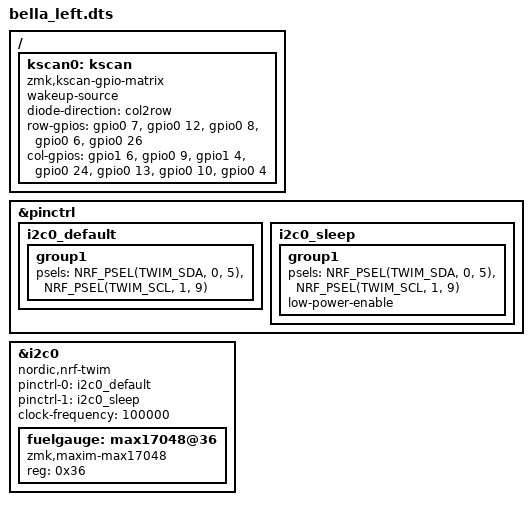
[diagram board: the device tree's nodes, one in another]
/*
 * Copyright (c) 2023 The ZMK Contributors
 *
 * SPDX-License-Identifier: MIT
 */

#include "bella.dtsi"

/{
kscan0: kscan {
    compatible = "zmk,kscan-gpio-matrix";
    wakeup-source;
    diode-direction = "col2row";
    row-gpios
        = <&gpio0 7 (GPIO_ACTIVE_HIGH | GPIO_PULL_DOWN)>
        , <&gpio0 12 (GPIO_ACTIVE_HIGH | GPIO_PULL_DOWN)>
        , <&gpio0 8 (GPIO_ACTIVE_HIGH | GPIO_PULL_DOWN)>
        , <&gpio0 6 (GPIO_ACTIVE_HIGH | GPIO_PULL_DOWN)>
        , <&gpio0 26 (GPIO_ACTIVE_HIGH | GPIO_PULL_DOWN)>
        ;
    col-gpios
        = <&gpio1 6 GPIO_ACTIVE_HIGH>
        , <&gpio0 9 GPIO_ACTIVE_HIGH>
        , <&gpio1 4 GPIO_ACTIVE_HIGH>
        , <&gpio0 24 GPIO_ACTIVE_HIGH>
        , <&gpio0 13 GPIO_ACTIVE_HIGH>
        , <&gpio0 10 GPIO_ACTIVE_HIGH>
        , <&gpio0 4 GPIO_ACTIVE_HIGH>
        ;
    };
};

&pinctrl {
     i2c0_default: i2c0_default {
        group1 {
        psels = <NRF_PSEL(TWIM_SDA, 0, 5)>,
                <NRF_PSEL(TWIM_SCL, 1, 9)>;
        };
    };
    i2c0_sleep: i2c0_sleep {
        group1 {
        psels = <NRF_PSEL(TWIM_SDA, 0, 5)>,
                <NRF_PSEL(TWIM_SCL, 1, 9)>;
        low-power-enable;
        };
    };
};

&i2c0 {
    status = "okay";
    compatible = "nordic,nrf-twim";
    pinctrl-0 = <&i2c0_default>;
    pinctrl-1 = <&i2c0_sleep>;
    pinctrl-names = "default", "sleep";
    clock-frequency = <100000>;

    fuelgauge: max17048@36 {
        compatible = "zmk,maxim-max17048";
        reg = <0x36>;
    };
};
